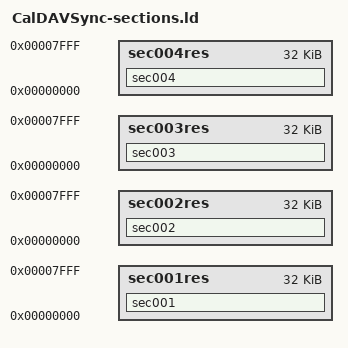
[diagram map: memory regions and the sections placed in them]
/* DO NOT EDIT!
   This file was automatically generated by m68k-palmos-multigen v2.3
   from CalDAVSync.def  */

MEMORY
{
	sec001res : ORIGIN = 0x0, LENGTH = 32768
	sec002res : ORIGIN = 0x0, LENGTH = 32768
	sec003res : ORIGIN = 0x0, LENGTH = 32768
	sec004res : ORIGIN = 0x0, LENGTH = 32768
}

SECTIONS
{
	sec001 : { *(sec001) } > sec001res
	sec002 : { *(sec002) } > sec002res
	sec003 : { *(sec003) } > sec003res
	sec004 : { *(sec004) } > sec004res
}
